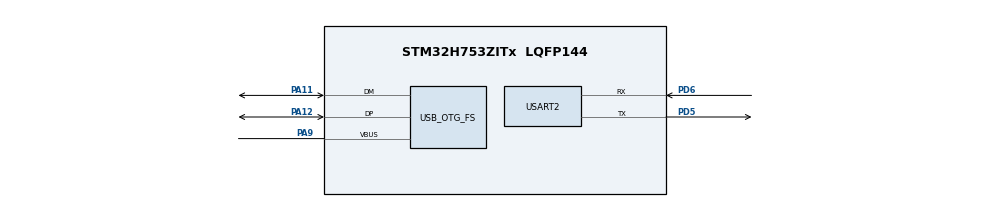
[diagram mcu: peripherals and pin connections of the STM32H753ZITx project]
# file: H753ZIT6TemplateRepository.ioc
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CORTEX_M7.default_mode_Activation=1
FREERTOS.Tasks01=defaultTask,0,192,StartDefaultTask,Default,NULL,Dynamic,NULL,NULL
FREERTOS.configMINIMAL_STACK_SIZE=192
FREERTOS.configTOTAL_HEAP_SIZE=64000
FREERTOS.configUSE_NEWLIB_REENTRANT=1
FREERTOS.configUSE_TIMERS=1
Mcu.Family=STM32H7
Mcu.Name=STM32H753ZITx
Mcu.Package=LQFP144
NVIC.OTG_FS_IRQn=true\:5\:0\:false\:false\:true\:true\:false\:true\:true
NVIC.PriorityGroup=NVIC_PRIORITYGROUP_4
NVIC.TIM2_IRQn=true\:15\:0\:false\:false\:true\:false\:false\:true\:true
NVIC.TimeBase=TIM2_IRQn
NVIC.TimeBaseIP=TIM2
NVIC.USART2_IRQn=true\:5\:0\:false\:false\:true\:true\:true\:true\:true
PA11.Mode=Device_Only
PA11.Signal=USB_OTG_FS_DM
PA12.Mode=Device_Only
PA12.Signal=USB_OTG_FS_DP
PA9.Mode=Activate_VBUS
PA9.Signal=USB_OTG_FS_VBUS
PD5.Mode=Asynchronous
PD5.Signal=USART2_TX
PD6.Mode=Asynchronous
PD6.Signal=USART2_RX
ProjectManager.HeapSize=0x200
ProjectManager.StackSize=0x400
ProjectManager.TargetToolchain=STM32CubeIDE
RCC.ADCFreq_Value=129000000
RCC.APB1Freq_Value=32000000
RCC.APB2Freq_Value=64000000
RCC.APB3Freq_Value=64000000
RCC.APB4Freq_Value=64000000
RCC.CortexFreq_Value=64000000
RCC.D2PPRE1=RCC_APB1_DIV2
RCC.HCLKFreq_Value=64000000
RCC.SYSCLKFreq_VALUE=64000000
RCC.USBCLockSelection=RCC_USBCLKSOURCE_HSI48
RCC.USBFreq_Value=48000000
USART2.VirtualMode-Asynchronous=VM_ASYNC
USB_DEVICE.CLASS_NAME_FS=MSC
USB_DEVICE.VirtualMode-MSC_FS=Msc
USB_DEVICE.VirtualModeFS=Msc_FS
USB_OTG_FS.VirtualMode=Device_Only
VP_CRC_VS_CRC.Mode=CRC_Activate
VP_FATFS_VS_Generic.Mode=User_defined
VP_FREERTOS_VS_CMSIS_V1.Mode=CMSIS_V1
VP_MEMORYMAP_VS_MEMORYMAP.Mode=CurAppReg
VP_SYS_VS_tim2.Mode=TIM2
VP_USB_DEVICE_VS_USB_DEVICE_MSC_FS.Mode=MSC_FS
board=custom

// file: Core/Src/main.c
/* USER CODE BEGIN Header */
/**
  ******************************************************************************
  * @file           : main.c
  * @brief          : Main program body
  ******************************************************************************
  * @attention
  *
  * Copyright (c) 2025 STMicroelectronics.
  * All rights reserved.
  *
  * This software is licensed under terms that can be found in the LICENSE file
  * in the root directory of this software component.
  * If no LICENSE file comes with this software, it is provided AS-IS.
  *
  ******************************************************************************
  */
/* USER CODE END Header */
#include "main.h"
#include "cmsis_os.h"
#include "fatfs.h"
#include "usb_device.h"

/* USER CODE BEGIN Includes */
#include "RunInterface.hpp"
#include "fatfs.h"

/* USER CODE END Includes */

CRC_HandleTypeDef hcrc;

osThreadId defaultTaskHandle;

void SystemClock_Config(void);
static void MPU_Config(void);
static void MX_GPIO_Init(void);
static void MX_CRC_Init(void);
static void MX_USART2_UART_Init(void);
void StartDefaultTask(void const * argument);

int main(void)
{

  /* MPU Configuration--------------------------------------------------------*/
  MPU_Config();

  /* MCU Configuration--------------------------------------------------------*/

  /* Reset of all peripherals, Initializes the Flash interface and the Systick. */
  HAL_Init();

  /* Configure the system clock */
  SystemClock_Config();

  /* Initialize all configured peripherals */
  MX_GPIO_Init();
  MX_CRC_Init();
  MX_USART2_UART_Init();
  MX_FATFS_Init();
  /* USER CODE BEGIN 2 */

  run_interface();
  #if 0
  /* USER CODE END 2 */

  /* Create the thread(s) */
  /* definition and creation of defaultTask */
  osThreadDef(defaultTask, StartDefaultTask, osPriorityNormal, 0, 192);
  defaultTaskHandle = osThreadCreate(osThread(defaultTask), NULL);

  /* Start scheduler */
  osKernelStart();

  /* We should never get here as control is now taken by the scheduler */

  /* Infinite loop */
  while (1)
  {

    /* USER CODE BEGIN 3 */
  }
  #endif
  /* USER CODE END 3 */
}

void SystemClock_Config(void)
{
  RCC_OscInitTypeDef RCC_OscInitStruct = {0};
  RCC_ClkInitTypeDef RCC_ClkInitStruct = {0};

  /** Supply configuration update enable
  */
  HAL_PWREx_ConfigSupply(PWR_LDO_SUPPLY);

  /** Configure the main internal regulator output voltage
  */
  __HAL_PWR_VOLTAGESCALING_CONFIG(PWR_REGULATOR_VOLTAGE_SCALE3);

  while(!__HAL_PWR_GET_FLAG(PWR_FLAG_VOSRDY)) {}

  /** Initializes the RCC Oscillators according to the specified parameters
  * in the RCC_OscInitTypeDef structure.
  */
  RCC_OscInitStruct.OscillatorType = RCC_OSCILLATORTYPE_HSI48|RCC_OSCILLATORTYPE_HSI;
  RCC_OscInitStruct.HSIState = RCC_HSI_DIV1;
  RCC_OscInitStruct.HSICalibrationValue = RCC_HSICALIBRATION_DEFAULT;
  RCC_OscInitStruct.HSI48State = RCC_HSI48_ON;
  RCC_OscInitStruct.PLL.PLLState = RCC_PLL_NONE;
  if (HAL_RCC_OscConfig(&RCC_OscInitStruct) != HAL_OK)
  {
    Error_Handler();
  }

  /** Initializes the CPU, AHB and APB buses clocks
  */
  RCC_ClkInitStruct.ClockType = RCC_CLOCKTYPE_HCLK|RCC_CLOCKTYPE_SYSCLK
                              |RCC_CLOCKTYPE_PCLK1|RCC_CLOCKTYPE_PCLK2
                              |RCC_CLOCKTYPE_D3PCLK1|RCC_CLOCKTYPE_D1PCLK1;
  RCC_ClkInitStruct.SYSCLKSource = RCC_SYSCLKSOURCE_HSI;
  RCC_ClkInitStruct.SYSCLKDivider = RCC_SYSCLK_DIV1;
  RCC_ClkInitStruct.AHBCLKDivider = RCC_HCLK_DIV1;
  RCC_ClkInitStruct.APB3CLKDivider = RCC_APB3_DIV1;
  RCC_ClkInitStruct.APB1CLKDivider = RCC_APB1_DIV2;
  RCC_ClkInitStruct.APB2CLKDivider = RCC_APB2_DIV1;
  RCC_ClkInitStruct.APB4CLKDivider = RCC_APB4_DIV1;

  if (HAL_RCC_ClockConfig(&RCC_ClkInitStruct, FLASH_LATENCY_1) != HAL_OK)
  {
    Error_Handler();
  }
}

static void MX_CRC_Init(void)
{

  hcrc.Instance = CRC;
  hcrc.Init.DefaultPolynomialUse = DEFAULT_POLYNOMIAL_ENABLE;
  hcrc.Init.DefaultInitValueUse = DEFAULT_INIT_VALUE_ENABLE;
  hcrc.Init.InputDataInversionMode = CRC_INPUTDATA_INVERSION_NONE;
  hcrc.Init.OutputDataInversionMode = CRC_OUTPUTDATA_INVERSION_DISABLE;
  hcrc.InputDataFormat = CRC_INPUTDATA_FORMAT_BYTES;
  if (HAL_CRC_Init(&hcrc) != HAL_OK)
  {
    Error_Handler();
  }

}

static void MX_USART2_UART_Init(void)
{

  LL_USART_InitTypeDef USART_InitStruct = {0};

  LL_GPIO_InitTypeDef GPIO_InitStruct = {0};
  RCC_PeriphCLKInitTypeDef PeriphClkInitStruct = {0};

  /** Initializes the peripherals clock
  */
  PeriphClkInitStruct.PeriphClockSelection = RCC_PERIPHCLK_USART2;
  PeriphClkInitStruct.Usart234578ClockSelection = RCC_USART234578CLKSOURCE_D2PCLK1;
  if (HAL_RCCEx_PeriphCLKConfig(&PeriphClkInitStruct) != HAL_OK)
  {
    Error_Handler();
  }

  /* Peripheral clock enable */
  LL_APB1_GRP1_EnableClock(LL_APB1_GRP1_PERIPH_USART2);

  LL_AHB4_GRP1_EnableClock(LL_AHB4_GRP1_PERIPH_GPIOD);
  /**USART2 GPIO Configuration
  PD5   ------> USART2_TX
  PD6   ------> USART2_RX
  */
  GPIO_InitStruct.Pin = LL_GPIO_PIN_5|LL_GPIO_PIN_6;
  GPIO_InitStruct.Mode = LL_GPIO_MODE_ALTERNATE;
  GPIO_InitStruct.Speed = LL_GPIO_SPEED_FREQ_LOW;
  GPIO_InitStruct.OutputType = LL_GPIO_OUTPUT_PUSHPULL;
  GPIO_InitStruct.Pull = LL_GPIO_PULL_NO;
  GPIO_InitStruct.Alternate = LL_GPIO_AF_7;
  LL_GPIO_Init(GPIOD, &GPIO_InitStruct);

  /* USART2 interrupt Init */
  NVIC_SetPriority(USART2_IRQn, NVIC_EncodePriority(NVIC_GetPriorityGrouping(),5, 0));
  NVIC_EnableIRQ(USART2_IRQn);

  USART_InitStruct.PrescalerValue = LL_USART_PRESCALER_DIV1;
  USART_InitStruct.BaudRate = 115200;
  USART_InitStruct.DataWidth = LL_USART_DATAWIDTH_8B;
  USART_InitStruct.StopBits = LL_USART_STOPBITS_1;
  USART_InitStruct.Parity = LL_USART_PARITY_NONE;
  USART_InitStruct.TransferDirection = LL_USART_DIRECTION_TX_RX;
  USART_InitStruct.HardwareFlowControl = LL_USART_HWCONTROL_NONE;
  USART_InitStruct.OverSampling = LL_USART_OVERSAMPLING_16;
  LL_USART_Init(USART2, &USART_InitStruct);
  LL_USART_SetTXFIFOThreshold(USART2, LL_USART_FIFOTHRESHOLD_1_8);
  LL_USART_SetRXFIFOThreshold(USART2, LL_USART_FIFOTHRESHOLD_1_8);
  LL_USART_DisableFIFO(USART2);
  LL_USART_ConfigAsyncMode(USART2);

  LL_USART_Enable(USART2);

  /* Polling USART2 initialisation */
  while((!(LL_USART_IsActiveFlag_TEACK(USART2))) || (!(LL_USART_IsActiveFlag_REACK(USART2))))
  {
  }

}

static void MX_GPIO_Init(void)
{

  /* GPIO Ports Clock Enable */
  __HAL_RCC_GPIOA_CLK_ENABLE();
  __HAL_RCC_GPIOD_CLK_ENABLE();

}

void StartDefaultTask(void const * argument)
{
  /* init code for USB_DEVICE */
  MX_USB_DEVICE_Init();
  for(;;)
  {
    osDelay(1);
  }
}

 /* MPU Configuration */

void MPU_Config(void)
{
  MPU_Region_InitTypeDef MPU_InitStruct = {0};

  /* Disables the MPU */
  HAL_MPU_Disable();

  /** Initializes and configures the Region and the memory to be protected
  */
  MPU_InitStruct.Enable = MPU_REGION_ENABLE;
  MPU_InitStruct.Number = MPU_REGION_NUMBER0;
  MPU_InitStruct.BaseAddress = 0x0;
  MPU_InitStruct.Size = MPU_REGION_SIZE_4GB;
  MPU_InitStruct.SubRegionDisable = 0x87;
  MPU_InitStruct.TypeExtField = MPU_TEX_LEVEL0;
  MPU_InitStruct.AccessPermission = MPU_REGION_NO_ACCESS;
  MPU_InitStruct.DisableExec = MPU_INSTRUCTION_ACCESS_DISABLE;
  MPU_InitStruct.IsShareable = MPU_ACCESS_SHAREABLE;
  MPU_InitStruct.IsCacheable = MPU_ACCESS_NOT_CACHEABLE;
  MPU_InitStruct.IsBufferable = MPU_ACCESS_NOT_BUFFERABLE;

  HAL_MPU_ConfigRegion(&MPU_InitStruct);
  /* Enables the MPU */
  HAL_MPU_Enable(MPU_PRIVILEGED_DEFAULT);

}

void HAL_TIM_PeriodElapsedCallback(TIM_HandleTypeDef *htim)
{
  if (htim->Instance == TIM2)
  {
    HAL_IncTick();
  }
}

void Error_Handler(void)
{
  __disable_irq();
  while (1)
  {
  }
}
